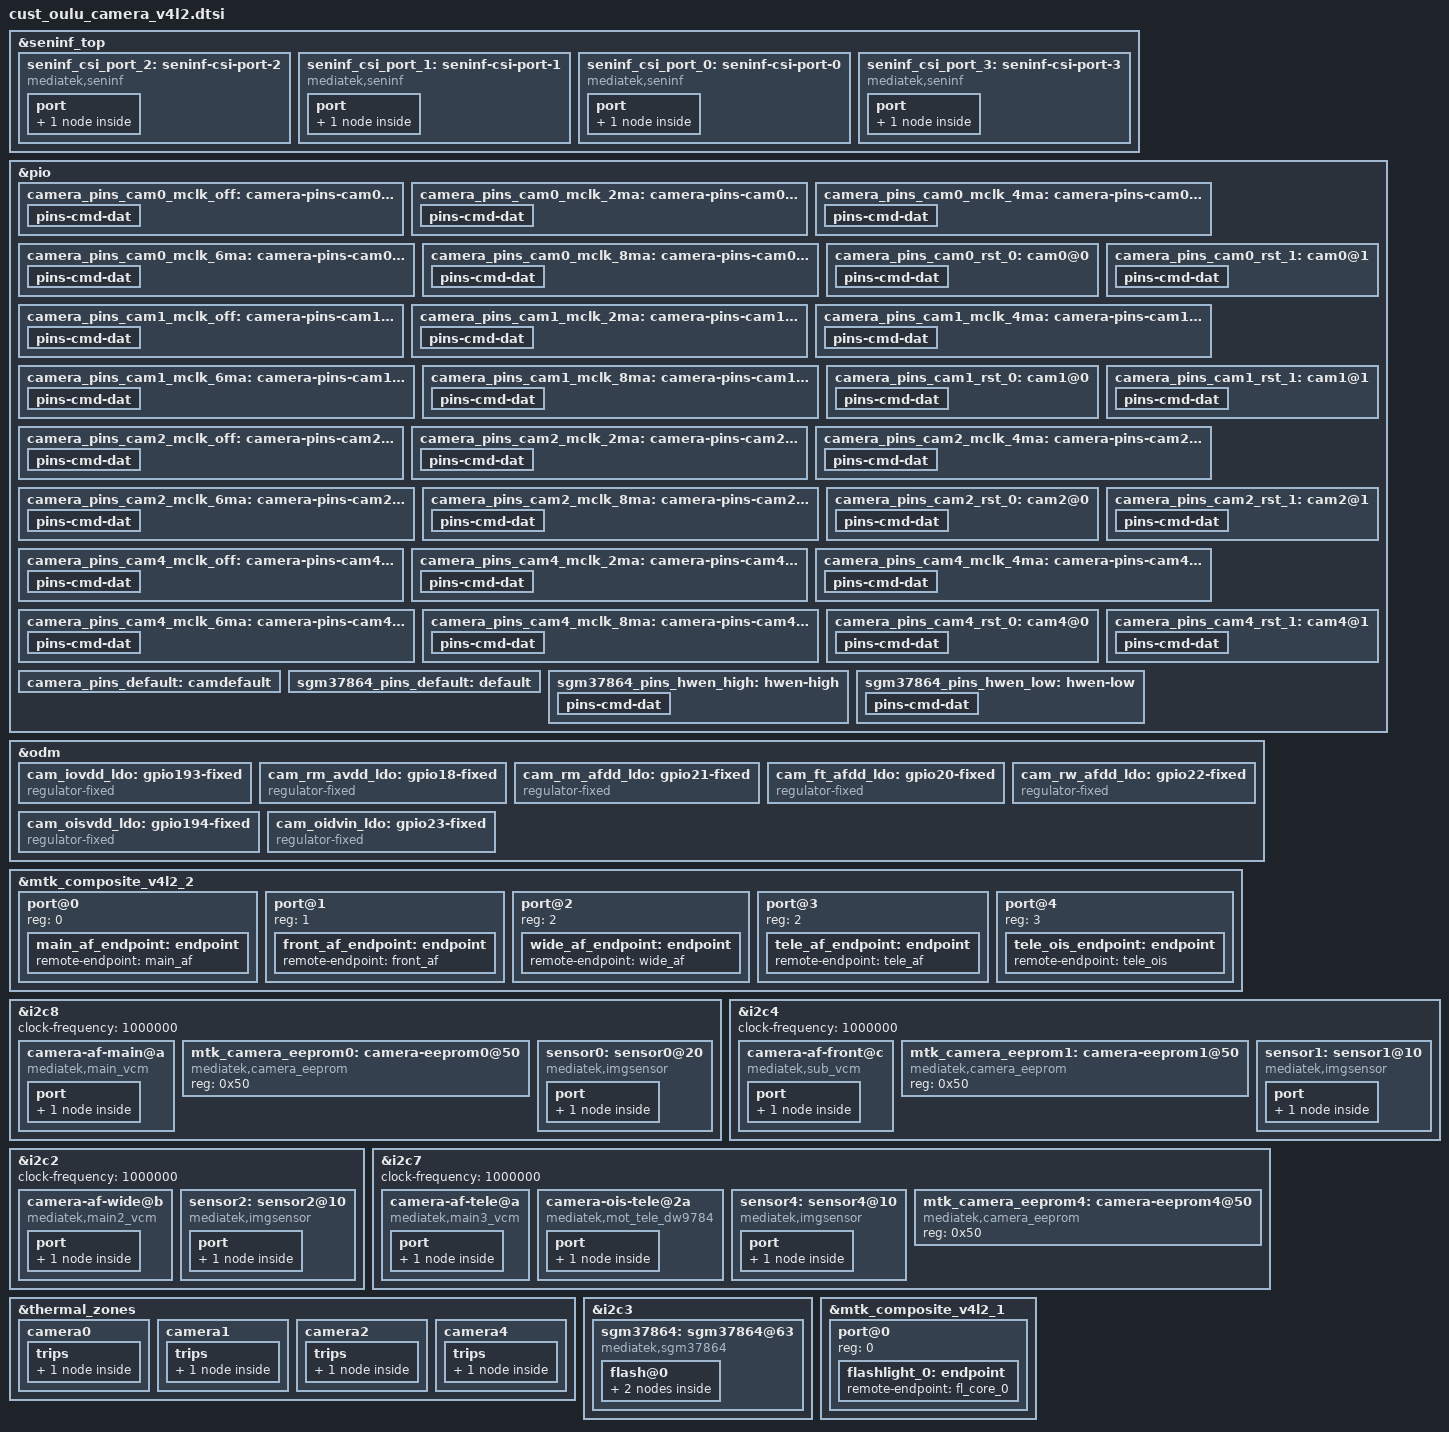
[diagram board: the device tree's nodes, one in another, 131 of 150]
// SPDX-License-Identifier: GPL-2.0
/* Copyright (c) 2020 MediaTek Inc. */
#include <dt-bindings/clock/mt6878-clk.h>
#include <mediatek/mot-oulu-external-camera-pmic.dtsi>

&seninf_top {
        seninf_csi_port_2: seninf-csi-port-2 {
            compatible = "mediatek,seninf";
            csi-port = "2";
            hs-trail-parameter = <0x20>;
            nvmem-cells = <&csi_efuse2>;
            nvmem-cell-names = "rg_csi";
            port {
                seninf_csi_port_2_in: endpoint {
                    remote-endpoint = <&sensor4_out>;
                };
            };
        };
        seninf_csi_port_1: seninf-csi-port-1 {
            compatible = "mediatek,seninf";
            csi-port = "1";
            dphy-settle-delay-dt = <20>;
            nvmem-cells = <&csi_efuse1>;
            nvmem-cell-names = "rg_csi";
            port {
                seninf_csi_port_1_in: endpoint {
                    remote-endpoint = <&sensor0_out>;
                };
            };
        };
        seninf_csi_port_0: seninf-csi-port-0 {
            compatible = "mediatek,seninf";
            csi-port = "0";
            dphy-settle-delay-dt = <17>;
            nvmem-cells = <&csi_efuse0>;
            nvmem-cell-names = "rg_csi";
            port {
                seninf_csi_port_0_in: endpoint {
                    remote-endpoint = <&sensor1_out>;
                };
            };
        };
        seninf_csi_port_3: seninf-csi-port-3 {
            compatible = "mediatek,seninf";
            csi-port = "3";
            dphy-settle-delay-dt = <17>;
            nvmem-cells = <&csi_efuse3>;
            nvmem-cell-names = "rg_csi";
            port {
                seninf_csi_port_3_in: endpoint {
                    remote-endpoint = <&sensor2_out>;
                };
            };
        };
};


/* CAMERA GPIO fixed to regulator */

&pio {
    camera_pins_cam0_mclk_off: camera-pins-cam0-mclk-off {
        pins-cmd-dat {
            pinmux = <PINMUX_GPIO94__FUNC_GPIO94>;
            drive-strength = <1>;
        };
    };
    camera_pins_cam0_mclk_2ma: camera-pins-cam0-mclk-2ma {
        pins-cmd-dat {
            pinmux = <PINMUX_GPIO94__FUNC_CMMCLK2>;
            drive-strength = <0>;
        };
    };
    camera_pins_cam0_mclk_4ma: camera-pins-cam0-mclk-4ma {
        pins-cmd-dat {
            pinmux = <PINMUX_GPIO94__FUNC_CMMCLK2>;
            drive-strength = <1>;
        };
    };
    camera_pins_cam0_mclk_6ma: camera-pins-cam0-mclk-6ma {
        pins-cmd-dat {
            pinmux = <PINMUX_GPIO94__FUNC_CMMCLK2>;
            drive-strength = <2>;
        };
    };
    camera_pins_cam0_mclk_8ma: camera-pins-cam0-mclk-8ma {
        pins-cmd-dat {
            pinmux = <PINMUX_GPIO94__FUNC_CMMCLK2>;
            drive-strength = <3>;
        };
    };
    camera_pins_cam0_rst_0: cam0@0 {
        pins-cmd-dat {
            pinmux = <PINMUX_GPIO26__FUNC_GPIO26>;
            slew-rate = <1>;
            output-low;
        };
    };
    camera_pins_cam0_rst_1: cam0@1 {
        pins-cmd-dat {
            pinmux = <PINMUX_GPIO26__FUNC_GPIO26>;
            slew-rate = <1>;
            output-high;
        };
    };


    camera_pins_cam1_mclk_off: camera-pins-cam1-mclk-off {
        pins-cmd-dat {
            pinmux = <PINMUX_GPIO96__FUNC_GPIO96>;
            drive-strength = <1>;
        };
    };
    camera_pins_cam1_mclk_2ma: camera-pins-cam1-mclk-2ma {
        pins-cmd-dat {
            pinmux = <PINMUX_GPIO96__FUNC_CMMCLK4>;
            drive-strength = <0>;
        };
    };
    camera_pins_cam1_mclk_4ma: camera-pins-cam1-mclk-4ma {
        pins-cmd-dat {
            pinmux = <PINMUX_GPIO96__FUNC_CMMCLK4>;
            drive-strength = <1>;
        };
    };
    camera_pins_cam1_mclk_6ma: camera-pins-cam1-mclk-6ma {
        pins-cmd-dat {
            pinmux = <PINMUX_GPIO96__FUNC_CMMCLK4>;
            drive-strength = <2>;
        };
    };
    camera_pins_cam1_mclk_8ma: camera-pins-cam1-mclk-8ma {
        pins-cmd-dat {
            pinmux = <PINMUX_GPIO96__FUNC_CMMCLK4>;
            drive-strength = <3>;
        };
    };
    camera_pins_cam1_rst_0: cam1@0 {
        pins-cmd-dat {
            pinmux = <PINMUX_GPIO82__FUNC_GPIO82>;
            slew-rate = <1>;
            output-low;
        };
    };
    camera_pins_cam1_rst_1: cam1@1 {
        pins-cmd-dat {
            pinmux = <PINMUX_GPIO82__FUNC_GPIO82>;
            slew-rate = <1>;
            output-high;
        };
    };
    camera_pins_cam2_mclk_off: camera-pins-cam2-mclk-off {
        pins-cmd-dat {
            pinmux = <PINMUX_GPIO95__FUNC_GPIO95>;
            drive-strength = <1>;
        };
    };
    camera_pins_cam2_mclk_2ma: camera-pins-cam2-mclk-2ma {
        pins-cmd-dat {
            pinmux = <PINMUX_GPIO95__FUNC_CMMCLK3>;
            drive-strength = <0>;
        };
    };
    camera_pins_cam2_mclk_4ma: camera-pins-cam2-mclk-4ma {
        pins-cmd-dat {
            pinmux = <PINMUX_GPIO95__FUNC_CMMCLK3>;
            drive-strength = <1>;
        };
    };
    camera_pins_cam2_mclk_6ma: camera-pins-cam2-mclk-6ma {
        pins-cmd-dat {
            pinmux = <PINMUX_GPIO95__FUNC_CMMCLK3>;
            drive-strength = <2>;
        };
    };
    camera_pins_cam2_mclk_8ma: camera-pins-cam2-mclk-8ma {
        pins-cmd-dat {
            pinmux = <PINMUX_GPIO95__FUNC_CMMCLK3>;
            drive-strength = <3>;
        };
    };
    camera_pins_cam2_rst_0: cam2@0 {
        pins-cmd-dat {
            pinmux = <PINMUX_GPIO25__FUNC_GPIO25>;
            slew-rate = <1>;
            output-low;
        };
    };
    camera_pins_cam2_rst_1: cam2@1 {
        pins-cmd-dat {
            pinmux = <PINMUX_GPIO25__FUNC_GPIO25>;
            slew-rate = <1>;
            output-high;
        };
    };

    camera_pins_cam4_mclk_off: camera-pins-cam4-mclk-off {
        pins-cmd-dat {
            pinmux = <PINMUX_GPIO93__FUNC_GPIO93>;
            drive-strength = <1>;
        };
    };
    camera_pins_cam4_mclk_2ma: camera-pins-cam4-mclk-2ma {
        pins-cmd-dat {
            pinmux = <PINMUX_GPIO93__FUNC_CMMCLK1>;
            drive-strength = <0>;
        };
    };
    camera_pins_cam4_mclk_4ma: camera-pins-cam4-mclk-4ma {
        pins-cmd-dat {
            pinmux = <PINMUX_GPIO93__FUNC_CMMCLK1>;
            drive-strength = <1>;
        };
    };
    camera_pins_cam4_mclk_6ma: camera-pins-cam4-mclk-6ma {
        pins-cmd-dat {
            pinmux = <PINMUX_GPIO93__FUNC_CMMCLK1>;
            drive-strength = <2>;
        };
    };
    camera_pins_cam4_mclk_8ma: camera-pins-cam4-mclk-8ma {
        pins-cmd-dat {
            pinmux = <PINMUX_GPIO93__FUNC_CMMCLK1>;
            drive-strength = <3>;
        };
    };
    camera_pins_cam4_rst_0: cam4@0 {
        pins-cmd-dat {
            pinmux = <PINMUX_GPIO27__FUNC_GPIO27>;
            slew-rate = <1>;
            output-low;
        };
    };
    camera_pins_cam4_rst_1: cam4@1 {
        pins-cmd-dat {
            pinmux = <PINMUX_GPIO27__FUNC_GPIO27>;
            slew-rate = <1>;
            output-high;
        };
    };

    //add for main ois -
    camera_pins_default: camdefault {
    };
};
/* CAMERA GPIO end */

&odm {
        cam_iovdd_ldo: gpio193-fixed {
            compatible = "regulator-fixed";
            regulator-name = "cam_iovdd_gpio_regulator";
            regulator-min-microvolt = <1800000>;
            regulator-max-microvolt = <1800000>;
            enable-active-high;
            gpio = <&pio 193 0x0>;
        };
        cam_rm_avdd_ldo: gpio18-fixed {
            compatible = "regulator-fixed";
            regulator-name = "rm_avdd_gpio_regulator";
            regulator-min-microvolt = <1800000>;
            regulator-max-microvolt = <1800000>;
            enable-active-high;
            gpio = <&pio 18 0x0>;
        };
        cam_rm_afdd_ldo: gpio21-fixed {
            compatible = "regulator-fixed";
            regulator-name = "rm_afdd_gpio_regulator";
            regulator-min-microvolt = <2800000>;
            regulator-max-microvolt = <2800000>;
            enable-active-high;
            gpio = <&pio 21 0x0>;
        };
        cam_ft_afdd_ldo: gpio20-fixed {
            compatible = "regulator-fixed";
            regulator-name = "ft_afdd_gpio_regulator";
            regulator-min-microvolt = <2800000>;
            regulator-max-microvolt = <2800000>;
            enable-active-high;
            gpio = <&pio 20 0x0>;
        };
        cam_rw_afdd_ldo: gpio22-fixed {
            compatible = "regulator-fixed";
            regulator-name = "rw_afdd_gpio_regulator";
            regulator-min-microvolt = <2800000>;
            regulator-max-microvolt = <2800000>;
            enable-active-high;
            gpio = <&pio 22 0x0>;
        };

        cam_oisvdd_ldo: gpio194-fixed {
            compatible = "regulator-fixed";
            regulator-name = "vcama_gpio_regulator";
            regulator-min-microvolt = <2800000>;
            regulator-max-microvolt = <2800000>;
            enable-active-high;
            gpio = <&pio 194 0x0>;
        };

        cam_oidvin_ldo: gpio23-fixed {
            compatible = "regulator-fixed";
            regulator-name = "vcamd_gpio_regulator";
            regulator-min-microvolt = <2800000>;
            regulator-max-microvolt = <2800000>;
            enable-active-high;
            gpio = <&pio 23 0x0>;
        };
};

&mtk_composite_v4l2_2 {
    #address-cells = <1>;
    #size-cells = <0>;
    port@0 {
        reg = <0>;
        main_af_endpoint: endpoint {
            remote-endpoint = <&main_af>;
        };
    };
    port@1 {
        reg = <1>;
        front_af_endpoint: endpoint {
            remote-endpoint = <&front_af>;
        };
    };
    port@2 {
        reg = <2>;
        wide_af_endpoint: endpoint {
            remote-endpoint = <&wide_af>;
        };
    };

    port@3 {
        reg = <2>;
        tele_af_endpoint: endpoint {
            remote-endpoint = <&tele_af>;
        };
    };
    port@4 {
        reg = <3>;
        tele_ois_endpoint: endpoint {
            remote-endpoint = <&tele_ois>;
        };
    };
};

&i2c8 {
    status = "okay";
    clock-frequency = <1000000>;

    camera-af-main@a {
        compatible = "mediatek,main_vcm";
        reg = <0x0a>;
        vin-supply = <&cam_rm_afdd_ldo>;
        port {
            main_af: endpoint {
                remote-endpoint = <&main_af_endpoint>;
            };
        };
    };

    mtk_camera_eeprom0:camera-eeprom0@50 {
        compatible = "mediatek,camera_eeprom";
        reg = <0x50>;
        status = "okay";
    };

    sensor0: sensor0@20 {
        compatible = "mediatek,imgsensor";
        sensor-names = "mot_oulu_imx896_mipi_raw";
        reg = <0x20>;

        #thermal-sensor-cells = <0>;

        pinctrl-names = "mclk_off",
                "mclk_2mA",
                "mclk_4mA",
                "mclk_6mA",
                "mclk_8mA",
                "rst_low",
                "rst_high";

        pinctrl-0 = <&camera_pins_cam0_mclk_off>;
        pinctrl-1 = <&camera_pins_cam0_mclk_2ma>;
        pinctrl-2 = <&camera_pins_cam0_mclk_4ma>;
        pinctrl-3 = <&camera_pins_cam0_mclk_6ma>;
        pinctrl-4 = <&camera_pins_cam0_mclk_8ma>;
        pinctrl-5 = <&camera_pins_cam0_rst_0>;
        pinctrl-6 = <&camera_pins_cam0_rst_1>;

        dvdd-supply = <&cam_rm_dvdd_ldo>;
        avdd-supply = <&cam_rm_avdd_ldo>;
        avdd2-supply = <&cam_rm_avdd2_ldo>;
        afvdd-supply = <&cam_rm_afdd_ldo>;
        dovdd-supply = <&cam_iovdd_ldo>;

        clocks = <&topckgen_clk CLK_TOP_UVPLL192M_D32>,
            <&topckgen_clk CLK_TOP_UVPLL192M_D16>,
            <&topckgen_clk CLK_TOP_OSC_D20>,
            <&topckgen_clk CLK_TOP_UVPLL192M_D10>,
            <&topckgen_clk CLK_TOP_UVPLL192M_D8>,
            <&topckgen_clk CLK_TOP_TCK_26M_MX9>,
            <&topckgen_clk CLK_TOP_UNIVPLL_D6_D8>,
            <&topckgen_clk CLK_TOP_CAMTG3_SEL>;
        clock-names = "6", "12", "13", "19.2", "24", "26", "52", "mclk";


        status = "okay";
        port {
            sensor0_out: endpoint {
                remote-endpoint = <&seninf_csi_port_1_in>;
            };
        };
    };

};

&i2c4 {
    status = "okay";
    clock-frequency = <1000000>;

    camera-af-front@c {
        compatible = "mediatek,sub_vcm";
        reg = <0x0c>;
        vin-supply = <&cam_ft_afdd_ldo>;
        port {
            front_af: endpoint {
                remote-endpoint = <&front_af_endpoint>;
            };
        };
    };

    mtk_camera_eeprom1:camera-eeprom1@50 {
        compatible = "mediatek,camera_eeprom";
        reg = <0x50>;
        status = "okay";
    };

    sensor1: sensor1@10 {
        compatible = "mediatek,imgsensor";
        sensor-names = "mot_oulu_s5kjns_mipi_raw";
        reg = <0x10>;

        #thermal-sensor-cells = <0>;

        pinctrl-names = "mclk_off",
                "mclk_2mA",
                "mclk_4mA",
                "mclk_6mA",
                "mclk_8mA",
                "rst_low",
                "rst_high";
        pinctrl-0 = <&camera_pins_cam1_mclk_off>;
        pinctrl-1 = <&camera_pins_cam1_mclk_2ma>;
        pinctrl-2 = <&camera_pins_cam1_mclk_4ma>;
        pinctrl-3 = <&camera_pins_cam1_mclk_6ma>;
        pinctrl-4 = <&camera_pins_cam1_mclk_8ma>;
        pinctrl-5 = <&camera_pins_cam1_rst_0>;
        pinctrl-6 = <&camera_pins_cam1_rst_1>;
        dvdd-supply = <&cam_f_dvdd_ldo>;
        avdd-supply = <&cam_f_avdd_ldo>;
        dovdd-supply = <&cam_iovdd_ldo>;

        clocks = <&topckgen_clk CLK_TOP_UVPLL192M_D32>,
            <&topckgen_clk CLK_TOP_UVPLL192M_D16>,
            <&topckgen_clk CLK_TOP_OSC_D20>,
            <&topckgen_clk CLK_TOP_UVPLL192M_D10>,
            <&topckgen_clk CLK_TOP_UVPLL192M_D8>,
            <&topckgen_clk CLK_TOP_TCK_26M_MX9>,
            <&topckgen_clk CLK_TOP_UNIVPLL_D6_D8>,
            <&topckgen_clk CLK_TOP_CAMTG5_SEL>;
        clock-names = "6", "12", "13", "19.2", "24", "26", "52", "mclk";

        status = "okay";
        port {
            sensor1_out: endpoint {
                remote-endpoint = <&seninf_csi_port_0_in>;
            };
        };
    };
};

&i2c2 {
    status = "okay";
    clock-frequency = <1000000>;

    camera-af-wide@b {
        compatible = "mediatek,main2_vcm";
        reg = <0x0b>;
        vin-supply = <&cam_rw_afdd_ldo>;
        port {
            wide_af: endpoint {
                remote-endpoint = <&wide_af_endpoint>;
            };
        };
    };

    sensor2: sensor2@10 {
        compatible = "mediatek,imgsensor";
        sensor-names = "mot_oulu_s5kjns_uw_mipi_raw";
        reg = <0x10>;

        #thermal-sensor-cells = <0>;

        pinctrl-names = "mclk_off",
                "mclk_2mA",
                "mclk_4mA",
                "mclk_6mA",
                "mclk_8mA",
                "rst_low",
                "rst_high";
        pinctrl-0 = <&camera_pins_cam2_mclk_off>;
        pinctrl-1 = <&camera_pins_cam2_mclk_2ma>;
        pinctrl-2 = <&camera_pins_cam2_mclk_4ma>;
        pinctrl-3 = <&camera_pins_cam2_mclk_6ma>;
        pinctrl-4 = <&camera_pins_cam2_mclk_8ma>;
        pinctrl-5 = <&camera_pins_cam2_rst_0>;
        pinctrl-6 = <&camera_pins_cam2_rst_1>;

        avdd-supply = <&cam_rw_avdd_ldo>;
        dvdd-supply = <&cam_rw_dvdd_ldo>;
        dovdd-supply = <&cam_iovdd_ldo>;

        clocks = <&topckgen_clk CLK_TOP_UVPLL192M_D32>,
            <&topckgen_clk CLK_TOP_UVPLL192M_D16>,
            <&topckgen_clk CLK_TOP_OSC_D20>,
            <&topckgen_clk CLK_TOP_UVPLL192M_D10>,
            <&topckgen_clk CLK_TOP_UVPLL192M_D8>,
            <&topckgen_clk CLK_TOP_TCK_26M_MX9>,
            <&topckgen_clk CLK_TOP_UNIVPLL_D6_D8>,
            <&topckgen_clk CLK_TOP_CAMTG4_SEL>;
        clock-names = "6", "12", "13", "19.2", "24", "26", "52", "mclk";

        status = "okay";
        port {
            sensor2_out: endpoint {
                remote-endpoint = <&seninf_csi_port_3_in>;
            };
        };
    };
};

&i2c7 {
    status = "okay";
    clock-frequency = <1000000>;

    camera-af-tele@a {
        compatible = "mediatek,main3_vcm";
        reg = <0x0a>;
        vdd-supply = <&cam_oisvdd_ldo>;
        vin-supply = <&cam_oidvin_ldo>;

        status = "okay";
        port {
            tele_af: endpoint {
                remote-endpoint = <&tele_af_endpoint>;
            };
        };
    };

    camera-ois-tele@2a {
        compatible = "mediatek,mot_tele_dw9784";
        reg = <0x2a>;
        vdd-supply = <&cam_oisvdd_ldo>;
        vin-supply = <&cam_oidvin_ldo>;
        rst-supply = <&cam_iovdd_ldo>;

        status = "okay";
        port {
            tele_ois: endpoint {
                remote-endpoint = <&tele_ois_endpoint>;
            };
        };
    };

    sensor4: sensor4@10 {
        compatible = "mediatek,imgsensor";
        sensor-names = "mot_oulu_s5k3k1_mipi_raw";
        reg = <0x10>;

        #thermal-sensor-cells = <0>;

        pinctrl-names = "mclk_off",
                "mclk_2mA",
                "mclk_4mA",
                "mclk_6mA",
                "mclk_8mA",
                "rst_low",
                "rst_high";
        pinctrl-0 = <&camera_pins_cam4_mclk_off>;
        pinctrl-1 = <&camera_pins_cam4_mclk_2ma>;
        pinctrl-2 = <&camera_pins_cam4_mclk_4ma>;
        pinctrl-3 = <&camera_pins_cam4_mclk_6ma>;
        pinctrl-4 = <&camera_pins_cam4_mclk_8ma>;
        pinctrl-5 = <&camera_pins_cam4_rst_0>;
        pinctrl-6 = <&camera_pins_cam4_rst_1>;
        avdd-supply = <&cam_rt_avdd_ldo>;
        dvdd-supply = <&cam_rt_dvdd_ldo>;
        dovdd-supply = <&cam_iovdd_ldo>;

        clocks = <&topckgen_clk CLK_TOP_UVPLL192M_D32>,
            <&topckgen_clk CLK_TOP_UVPLL192M_D16>,
            <&topckgen_clk CLK_TOP_OSC_D20>,
            <&topckgen_clk CLK_TOP_UVPLL192M_D10>,
            <&topckgen_clk CLK_TOP_UVPLL192M_D8>,
            <&topckgen_clk CLK_TOP_TCK_26M_MX9>,
            <&topckgen_clk CLK_TOP_UNIVPLL_D6_D8>,
            <&topckgen_clk CLK_TOP_CAMTG2_SEL>;
        clock-names = "6", "12", "13", "19.2", "24", "26", "52", "mclk";

        status = "okay";
        port {
            sensor4_out: endpoint {
                remote-endpoint = <&seninf_csi_port_2_in>;
            };
        };
    };

    mtk_camera_eeprom4:camera-eeprom4@50 {
        compatible = "mediatek,camera_eeprom";
        reg = <0x50>;
        status = "okay";
    };

};

&thermal_zones {
    camera0: camera0 {
        polling-delay = <0>; /* milliseconds */
        polling-delay-passive = <0>; /* milliseconds */
        thermal-sensors = <&sensor0>;
        trips {
            camera0_crit: camera0-crit {
                temperature = <120000>;
                hysteresis = <2000>;
                type = "passive";
            };
        };
    };
    camera1: camera1 {
        polling-delay = <0>; /* milliseconds */
        polling-delay-passive = <0>; /* milliseconds */
        thermal-sensors = <&sensor1>;
        trips {
            camera1_crit: camera1-crit {
                temperature = <120000>;
                hysteresis = <2000>;
                type = "passive";
            };
        };
    };
    camera2: camera2 {
        polling-delay = <0>; /* milliseconds */
        polling-delay-passive = <0>; /* milliseconds */
        thermal-sensors = <&sensor2>;
        trips {
            camera2_crit: camera2-crit {
                temperature = <120000>;
                hysteresis = <2000>;
                type = "passive";
            };
        };
    };
    camera4: camera4 {
        polling-delay = <0>; /* milliseconds */
        polling-delay-passive = <0>; /* milliseconds */
        thermal-sensors = <&sensor4>;
        trips {
            camera4_crit: camera4-crit {
                temperature = <120000>;
                hysteresis = <2000>;
                type = "passive";
            };
        };
    };

};

&i2c3 {
    #address-cells = <1>;
    #size-cells = <0>;
    sgm37864:sgm37864@63 {
        compatible = "mediatek,sgm37864";
        #address-cells = <1>;
        #size-cells = <0>;
        reg = <0x63>;
        #cooling-cells = <2>;
        pinctrl-names = "default", "hwen-high", "hwen-low";
        pinctrl-0 = <&sgm37864_pins_default>;
        pinctrl-1 = <&sgm37864_pins_hwen_high>;
        pinctrl-2 = <&sgm37864_pins_hwen_low>;
        status = "okay";
        flash@0{
            reg = <0>;
            type = <0>;
            ct = <0>;
            part = <0>;
            port {
                fl_core_0: endpoint {
                    remote-endpoint = <&flashlight_0>;
                };
            };
        };
    };
};



&pio {
    sgm37864_pins_default: default {
    };

    sgm37864_pins_hwen_high: hwen-high {
        pins-cmd-dat {
            pinmux = <PINMUX_GPIO153__FUNC_GPIO153>;
            slew-rate = <1>;
            output-high;
        };
    };

    sgm37864_pins_hwen_low: hwen-low {
        pins-cmd-dat {
            pinmux = <PINMUX_GPIO153__FUNC_GPIO153>;
            slew-rate = <1>;
            output-low;
        };
    };
};


&mtk_composite_v4l2_1 {
    #address-cells = <1>;
    #size-cells = <0>;
    port@0 {
        reg = <0>;
        flashlight_0: endpoint {
            remote-endpoint = <&fl_core_0>;
        };
    };
};
